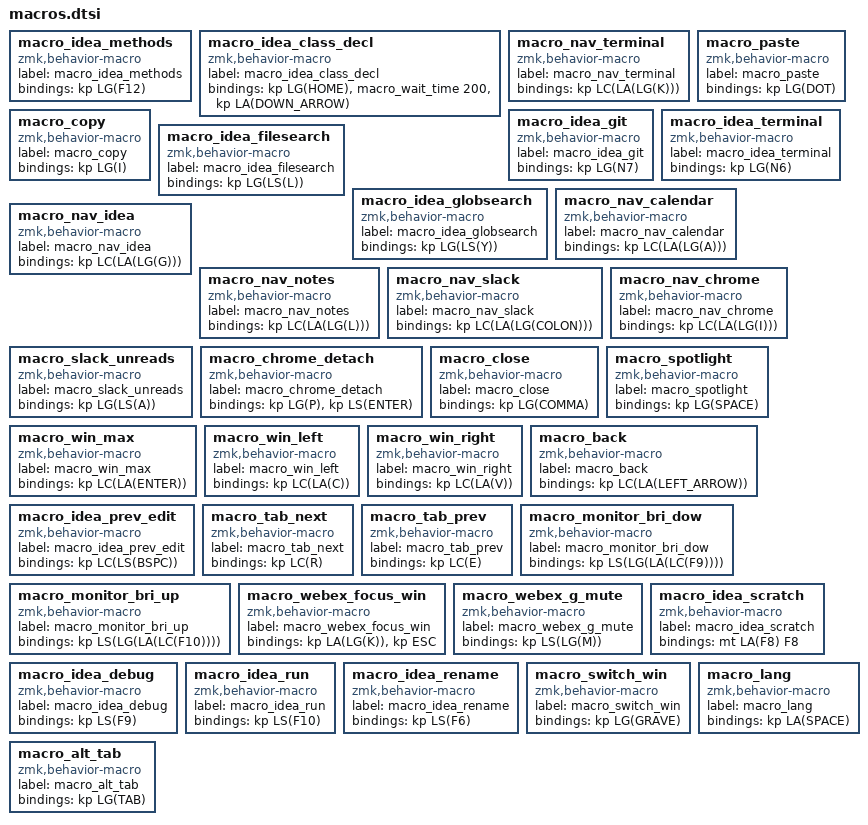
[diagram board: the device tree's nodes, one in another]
macro_idea_methods: macro_idea_methods{
compatible = "zmk,behavior-macro";
label = "macro_idea_methods";
#binding-cells = <0>;
bindings = <&kp LG(F12)>;
};
macro_idea_class_decl: macro_idea_class_decl{
compatible = "zmk,behavior-macro";
label = "macro_idea_class_decl";
#binding-cells = <0>;
bindings = <&kp LG(HOME)>, <&macro_wait_time 200>, <&kp LA(DOWN_ARROW)>;
};
macro_nav_terminal: macro_nav_terminal{
compatible = "zmk,behavior-macro";
label = "macro_nav_terminal";
#binding-cells = <0>;
bindings = <&kp LC(LA(LG(K)))>;
};
macro_paste: macro_paste{
compatible = "zmk,behavior-macro";
label = "macro_paste";
#binding-cells = <0>;
bindings = <&kp LG(DOT)>;
};
macro_copy: macro_copy{
compatible = "zmk,behavior-macro";
label = "macro_copy";
#binding-cells = <0>;
bindings = <&kp LG(I)>;
};
macro_idea_git: macro_idea_git{
compatible = "zmk,behavior-macro";
label = "macro_idea_git";
#binding-cells = <0>;
bindings = <&kp LG(N7)>;
};
macro_idea_terminal: macro_idea_terminal{
compatible = "zmk,behavior-macro";
label = "macro_idea_terminal";
#binding-cells = <0>;
bindings = <&kp LG(N6)>;
};
macro_idea_filesearch: macro_idea_filesearch{
compatible = "zmk,behavior-macro";
label = "macro_idea_filesearch";
#binding-cells = <0>;
bindings = <&kp LG(LS(L))>;
};
macro_idea_globsearch: macro_idea_globsearch{
compatible = "zmk,behavior-macro";
label = "macro_idea_globsearch";
#binding-cells = <0>;
bindings = <&kp LG(LS(Y))>;
};
macro_nav_calendar: macro_nav_calendar{
compatible = "zmk,behavior-macro";
label = "macro_nav_calendar";
#binding-cells = <0>;
bindings = <&kp LC(LA(LG(A)))>;
};
macro_nav_idea: macro_nav_idea{
compatible = "zmk,behavior-macro";
label = "macro_nav_idea";
#binding-cells = <0>;
bindings = <&kp LC(LA(LG(G)))>;
};
macro_nav_notes: macro_nav_notes{
compatible = "zmk,behavior-macro";
label = "macro_nav_notes";
#binding-cells = <0>;
bindings = <&kp LC(LA(LG(L)))>;
};
macro_nav_slack: macro_nav_slack{
compatible = "zmk,behavior-macro";
label = "macro_nav_slack";
#binding-cells = <0>;
bindings = <&kp LC(LA(LG(COLON)))>;
};
macro_nav_chrome: macro_nav_chrome{
compatible = "zmk,behavior-macro";
label = "macro_nav_chrome";
#binding-cells = <0>;
bindings = <&kp LC(LA(LG(I)))>;
};
macro_slack_unreads: macro_slack_unreads{
compatible = "zmk,behavior-macro";
label = "macro_slack_unreads";
#binding-cells = <0>;
bindings = <&kp LG(LS(A))>;
};
macro_chrome_detach: macro_chrome_detach{
compatible = "zmk,behavior-macro";
label = "macro_chrome_detach";
#binding-cells = <0>;
bindings = <&kp LG(P)>, <&kp LS(ENTER)>;
};
macro_close: macro_close{
compatible = "zmk,behavior-macro";
label = "macro_close";
#binding-cells = <0>;
bindings = <&kp LG(COMMA)>;
};
macro_spotlight: macro_spotlight{
compatible = "zmk,behavior-macro";
label = "macro_spotlight";
#binding-cells = <0>;
bindings = <&kp LG(SPACE)>;
};
macro_win_max: macro_win_max{
compatible = "zmk,behavior-macro";
label = "macro_win_max";
#binding-cells = <0>;
bindings = <&kp LC(LA(ENTER))>;
};
macro_win_left: macro_win_left{
compatible = "zmk,behavior-macro";
label = "macro_win_left";
#binding-cells = <0>;
bindings = <&kp LC(LA(C))>;
};
macro_win_right: macro_win_right{
compatible = "zmk,behavior-macro";
label = "macro_win_right";
#binding-cells = <0>;
bindings = <&kp LC(LA(V))>;
};
macro_back: macro_back{
compatible = "zmk,behavior-macro";
label = "macro_back";
#binding-cells = <0>;
bindings = <&kp LC(LA(LEFT_ARROW))>;
};
macro_idea_prev_edit: macro_idea_prev_edit{
compatible = "zmk,behavior-macro";
label = "macro_idea_prev_edit";
#binding-cells = <0>;
bindings = <&kp LC(LS(BSPC))>;
};
macro_tab_next: macro_tab_next{
compatible = "zmk,behavior-macro";
label = "macro_tab_next";
#binding-cells = <0>;
bindings = <&kp LC(R)>;
};
macro_tab_prev: macro_tab_prev{
compatible = "zmk,behavior-macro";
label = "macro_tab_prev";
#binding-cells = <0>;
bindings = <&kp LC(E)>;
};
macro_monitor_bri_dow: macro_monitor_bri_dow{
compatible = "zmk,behavior-macro";
label = "macro_monitor_bri_dow";
#binding-cells = <0>;
bindings = <&kp LS(LG(LA(LC(F9))))>;
};
macro_monitor_bri_up: macro_monitor_bri_up{
compatible = "zmk,behavior-macro";
label = "macro_monitor_bri_up";
#binding-cells = <0>;
bindings = <&kp LS(LG(LA(LC(F10))))>;
};
macro_webex_focus_win: macro_webex_focus_win{
compatible = "zmk,behavior-macro";
label = "macro_webex_focus_win";
#binding-cells = <0>;
bindings = <&kp LA(LG(K))>, <&kp ESC>;
};
macro_webex_g_mute: macro_webex_g_mute{
compatible = "zmk,behavior-macro";
label = "macro_webex_g_mute";
#binding-cells = <0>;
bindings = <&kp LS(LG(M))>;
};
macro_idea_scratch: macro_idea_scratch{
compatible = "zmk,behavior-macro";
label = "macro_idea_scratch";
#binding-cells = <0>;
bindings = <&mt LA(F8) F8>;
};
macro_idea_debug: macro_idea_debug{
compatible = "zmk,behavior-macro";
label = "macro_idea_debug";
#binding-cells = <0>;
bindings = <&kp LS(F9)>;
};
macro_idea_run: macro_idea_run{
compatible = "zmk,behavior-macro";
label = "macro_idea_run";
#binding-cells = <0>;
bindings = <&kp LS(F10)>;
};
macro_idea_rename: macro_idea_rename{
compatible = "zmk,behavior-macro";
label = "macro_idea_rename";
#binding-cells = <0>;
bindings = <&kp LS(F6)>;
};
macro_switch_win: macro_switch_win{
compatible = "zmk,behavior-macro";
label = "macro_switch_win";
#binding-cells = <0>;
bindings = <&kp LG(GRAVE)>;
};
macro_lang: macro_lang{
compatible = "zmk,behavior-macro";
label = "macro_lang";
#binding-cells = <0>;
bindings = <&kp LA(SPACE)>;
};
macro_alt_tab: macro_alt_tab{
compatible = "zmk,behavior-macro";
label = "macro_alt_tab";
#binding-cells = <0>;
bindings = <&kp LG(TAB)>;
};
